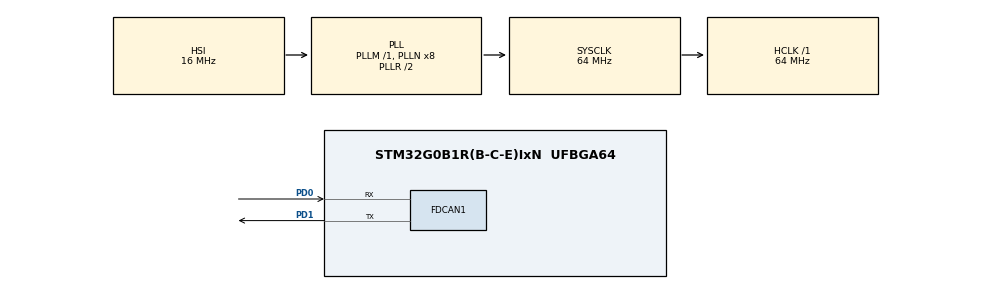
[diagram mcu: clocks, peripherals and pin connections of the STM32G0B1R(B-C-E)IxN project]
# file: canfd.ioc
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FDCAN1.AutoRetransmission=ENABLE
FDCAN1.CalculateBaudRateNominal=800000
FDCAN1.CalculateTimeBitNominal=1250
FDCAN1.CalculateTimeQuantumNominal=15.625
FDCAN1.DataPrescaler=1
FDCAN1.DataSyncJumpWidth=4
FDCAN1.DataTimeSeg1=5
FDCAN1.DataTimeSeg2=4
FDCAN1.ExtFiltersNbr=1
FDCAN1.FrameFormat=FDCAN_FRAME_FD_NO_BRS
FDCAN1.Mode=FDCAN_MODE_EXTERNAL_LOOPBACK
FDCAN1.NominalPrescaler=1
FDCAN1.NominalSyncJumpWidth=16
FDCAN1.NominalTimeSeg1=63
FDCAN1.NominalTimeSeg2=16
FDCAN1.StdFiltersNbr=1
FDCAN1.TransmitPause=ENABLE
Mcu.Family=STM32G0
Mcu.Name=STM32G0B1R(B-C-E)IxN
Mcu.Package=UFBGA64
NVIC.TIM16_FDCAN_IT0_IRQn=true\:0\:0\:false\:false\:true\:true\:true\:true
PD0.Mode=FDCAN_Activate
PD0.Signal=FDCAN1_RX
PD1.Mode=FDCAN_Activate
PD1.Signal=FDCAN1_TX
ProjectManager.HeapSize=0x200
ProjectManager.StackSize=0x400
ProjectManager.TargetToolchain=STM32CubeIDE
RCC.ADCFreq_Value=64000000
RCC.AHBFreq_Value=64000000
RCC.CortexFreq_Value=64000000
RCC.EXTERNAL_CLOCK_VALUE=48000
RCC.FDCANCLockSelection=RCC_FDCANCLKSOURCE_PLL
RCC.HCLKFreq_Value=64000000
RCC.HSE_VALUE=8000000
RCC.HSI48_VALUE=48000000
RCC.HSI_VALUE=16000000
RCC.LSE_VALUE=32768
RCC.SYSCLKFreq_VALUE=64000000
RCC.SYSCLKSource=RCC_SYSCLKSOURCE_PLLCLK
RCC.USBFreq_Value=48000000
RCC.VCOOutputFreq_Value=128000000
board=custom

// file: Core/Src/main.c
/* USER CODE BEGIN Header */
/**
  ******************************************************************************
  * @file           : main.c
  * @brief          : Main program body
  ******************************************************************************
  * @attention
  *
  * Copyright (c) 2023 STMicroelectronics.
  * All rights reserved.
  *
  * This software is licensed under terms that can be found in the LICENSE file
  * in the root directory of this software component.
  * If no LICENSE file comes with this software, it is provided AS-IS.
  *
  ******************************************************************************
  */
/* USER CODE END Header */
#include "main.h"

FDCAN_HandleTypeDef hfdcan1;

/* USER CODE BEGIN PV */
FDCAN_TxHeaderTypeDef TxHeader;
FDCAN_RxHeaderTypeDef RxHeader;
uint8_t TxData[12];
uint8_t RxData[12];
uint8_t indx = 0;

void HAL_FDCAN_RxFifo0Callback(FDCAN_HandleTypeDef *hfdcan, uint32_t RxFifo0ITs)
{
  if((RxFifo0ITs & FDCAN_IT_RX_FIFO0_NEW_MESSAGE) != RESET)
  {
    /* Retreive Rx messages from RX FIFO0 */
    if (HAL_FDCAN_GetRxMessage(hfdcan, FDCAN_RX_FIFO0, &RxHeader, RxData) != HAL_OK)
    {
    /* Reception Error */
    Error_Handler();
    }
    if (HAL_FDCAN_ActivateNotification(hfdcan, FDCAN_IT_RX_FIFO0_NEW_MESSAGE, 0) != HAL_OK)
    {
      /* Notification Error */
      Error_Handler();
    }
  }
}

/* USER CODE END PV */

void SystemClock_Config(void);
static void MX_GPIO_Init(void);
static void MX_FDCAN1_Init(void);

int main(void)
{

  /* MCU Configuration--------------------------------------------------------*/

  /* Reset of all peripherals, Initializes the Flash interface and the Systick. */
  HAL_Init();

  /* Configure the system clock */
  SystemClock_Config();

  /* Initialize all configured peripherals */
  MX_GPIO_Init();
  MX_FDCAN1_Init();
  /* USER CODE BEGIN 2 */

  /*##-2 Start FDCAN controller (continuous listening CAN bus) ##############*/
  if (HAL_FDCAN_Start(&hfdcan1) != HAL_OK) {
	  Error_Handler();
  }
  if (HAL_FDCAN_ActivateNotification(&hfdcan1, FDCAN_IT_RX_FIFO0_NEW_MESSAGE, 0) != HAL_OK) {
	  /* Notification Error */
	  Error_Handler();
  }

  TxHeader.Identifier = 0x11;
  TxHeader.IdType = FDCAN_STANDARD_ID;
  TxHeader.TxFrameType = FDCAN_DATA_FRAME;
  TxHeader.DataLength = FDCAN_DLC_BYTES_12;
  TxHeader.ErrorStateIndicator = FDCAN_ESI_ACTIVE;
  TxHeader.BitRateSwitch = FDCAN_BRS_OFF;
  TxHeader.FDFormat = FDCAN_FD_CAN;
  TxHeader.TxEventFifoControl = FDCAN_NO_TX_EVENTS;
  TxHeader.MessageMarker = 0;

  /* USER CODE END 2 */

  /* Infinite loop */
  /* USER CODE BEGIN WHILE */
  while (1)
  {
		for (int i=0; i<12; i++) {
		  TxData[i] = indx++;
		}

		if (HAL_FDCAN_AddMessageToTxFifoQ(&hfdcan1, &TxHeader, TxData)!= HAL_OK)
		{
		Error_Handler();
		}

		HAL_Delay (1000);
    /* USER CODE END WHILE */

  }
}

void SystemClock_Config(void)
{
  RCC_OscInitTypeDef RCC_OscInitStruct = {0};
  RCC_ClkInitTypeDef RCC_ClkInitStruct = {0};

  /** Configure the main internal regulator output voltage
  */
  HAL_PWREx_ControlVoltageScaling(PWR_REGULATOR_VOLTAGE_SCALE1);

  /** Initializes the RCC Oscillators according to the specified parameters
  * in the RCC_OscInitTypeDef structure.
  */
  RCC_OscInitStruct.OscillatorType = RCC_OSCILLATORTYPE_HSI;
  RCC_OscInitStruct.HSIState = RCC_HSI_ON;
  RCC_OscInitStruct.HSIDiv = RCC_HSI_DIV1;
  RCC_OscInitStruct.HSICalibrationValue = RCC_HSICALIBRATION_DEFAULT;
  RCC_OscInitStruct.PLL.PLLState = RCC_PLL_ON;
  RCC_OscInitStruct.PLL.PLLSource = RCC_PLLSOURCE_HSI;
  RCC_OscInitStruct.PLL.PLLM = RCC_PLLM_DIV1;
  RCC_OscInitStruct.PLL.PLLN = 8;
  RCC_OscInitStruct.PLL.PLLP = RCC_PLLP_DIV2;
  RCC_OscInitStruct.PLL.PLLQ = RCC_PLLQ_DIV2;
  RCC_OscInitStruct.PLL.PLLR = RCC_PLLR_DIV2;
  if (HAL_RCC_OscConfig(&RCC_OscInitStruct) != HAL_OK)
  {
    Error_Handler();
  }

  /** Initializes the CPU, AHB and APB buses clocks
  */
  RCC_ClkInitStruct.ClockType = RCC_CLOCKTYPE_HCLK|RCC_CLOCKTYPE_SYSCLK
                              |RCC_CLOCKTYPE_PCLK1;
  RCC_ClkInitStruct.SYSCLKSource = RCC_SYSCLKSOURCE_PLLCLK;
  RCC_ClkInitStruct.AHBCLKDivider = RCC_SYSCLK_DIV1;
  RCC_ClkInitStruct.APB1CLKDivider = RCC_HCLK_DIV1;

  if (HAL_RCC_ClockConfig(&RCC_ClkInitStruct, FLASH_LATENCY_2) != HAL_OK)
  {
    Error_Handler();
  }
}

static void MX_FDCAN1_Init(void)
{

  hfdcan1.Instance = FDCAN1;
  hfdcan1.Init.ClockDivider = FDCAN_CLOCK_DIV1;
  hfdcan1.Init.FrameFormat = FDCAN_FRAME_FD_NO_BRS;
  hfdcan1.Init.Mode = FDCAN_MODE_EXTERNAL_LOOPBACK;
  hfdcan1.Init.AutoRetransmission = ENABLE;
  hfdcan1.Init.TransmitPause = ENABLE;
  hfdcan1.Init.ProtocolException = DISABLE;
  hfdcan1.Init.NominalPrescaler = 1;
  hfdcan1.Init.NominalSyncJumpWidth = 16;
  hfdcan1.Init.NominalTimeSeg1 = 63;
  hfdcan1.Init.NominalTimeSeg2 = 16;
  hfdcan1.Init.DataPrescaler = 1;
  hfdcan1.Init.DataSyncJumpWidth = 4;
  hfdcan1.Init.DataTimeSeg1 = 5;
  hfdcan1.Init.DataTimeSeg2 = 4;
  hfdcan1.Init.StdFiltersNbr = 1;
  hfdcan1.Init.ExtFiltersNbr = 1;
  hfdcan1.Init.TxFifoQueueMode = FDCAN_TX_FIFO_OPERATION;
  if (HAL_FDCAN_Init(&hfdcan1) != HAL_OK)
  {
    Error_Handler();
  }
  /* USER CODE BEGIN FDCAN1_Init 2 */
  FDCAN_FilterTypeDef sFilterConfig;
  /*##-1 Configure the FDCAN filters ########################################*/
  /* Configure standard ID reception filter to Rx FIFO 0 */
  sFilterConfig.IdType = FDCAN_STANDARD_ID;
  sFilterConfig.FilterIndex = 0;
  sFilterConfig.FilterType = FDCAN_FILTER_MASK;
  sFilterConfig.FilterConfig = FDCAN_FILTER_TO_RXFIFO0;
  sFilterConfig.FilterID1 = 0x11;
  sFilterConfig.FilterID2 = 0x11;
  if (HAL_FDCAN_ConfigFilter(&hfdcan1, &sFilterConfig) != HAL_OK) {
	  Error_Handler();
  }
  /* USER CODE END FDCAN1_Init 2 */

}

static void MX_GPIO_Init(void)
{

  /* GPIO Ports Clock Enable */
  __HAL_RCC_GPIOD_CLK_ENABLE();

}

void Error_Handler(void)
{
  __disable_irq();
  while (1)
  {
  }
}
